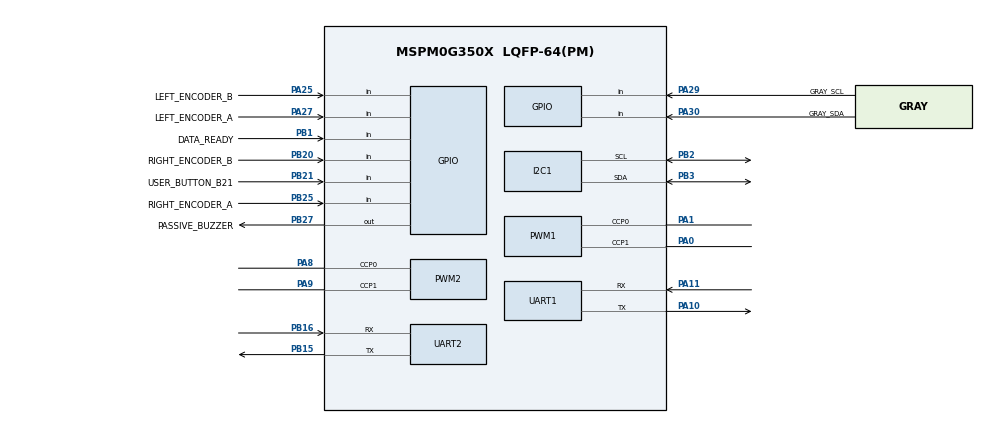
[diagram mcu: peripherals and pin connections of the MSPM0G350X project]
/**
 * @cliArgs --device "MSPM0G350X" --part "Default" --package "LQFP-64(PM)" --product "mspm0_sdk@2.11.00.07"
 * @versions {"tool":"1.26.2+4477"}
 */

/**
 * Import the modules used in this configuration.
 */
const GPIO   = scripting.addModule("/ti/driverlib/GPIO", {}, false);
const GPIO1  = GPIO.addInstance();
const GPIO2  = GPIO.addInstance();
const GPIO3  = GPIO.addInstance();
const GPIO4  = GPIO.addInstance();
const GPIO5  = GPIO.addInstance();
const I2C    = scripting.addModule("/ti/driverlib/I2C", {}, false);
const I2C1   = I2C.addInstance();
const PWM    = scripting.addModule("/ti/driverlib/PWM", {}, false);
const PWM1   = PWM.addInstance();
const PWM2   = PWM.addInstance();
const SYSCTL = scripting.addModule("/ti/driverlib/SYSCTL");
const TIMER  = scripting.addModule("/ti/driverlib/TIMER", {}, false);
const TIMER1 = TIMER.addInstance();
const UART   = scripting.addModule("/ti/driverlib/UART", {}, false);
const UART1  = UART.addInstance();
const UART2  = UART.addInstance();

/**
 * Write custom configuration values to the imported modules.
 */
GPIO1.$name                         = "ENCODERS";
GPIO1.associatedPins.create(4);
GPIO1.associatedPins[0].$name       = "LEFT_ENCODER_A";
GPIO1.associatedPins[0].direction   = "INPUT";
GPIO1.associatedPins[0].interruptEn = true;
GPIO1.associatedPins[0].polarity    = "RISE";
GPIO1.associatedPins[0].pin.$assign = "PA27";
GPIO1.associatedPins[1].$name       = "LEFT_ENCODER_B";
GPIO1.associatedPins[1].direction   = "INPUT";
GPIO1.associatedPins[1].pin.$assign = "PA25";
GPIO1.associatedPins[2].$name       = "RIGHT_ENCODER_A";
GPIO1.associatedPins[2].direction   = "INPUT";
GPIO1.associatedPins[2].interruptEn = true;
GPIO1.associatedPins[2].polarity    = "RISE";
GPIO1.associatedPins[2].pin.$assign = "PB25";
GPIO1.associatedPins[3].$name       = "RIGHT_ENCODER_B";
GPIO1.associatedPins[3].direction   = "INPUT";
GPIO1.associatedPins[3].pin.$assign = "PB20";

const Board = scripting.addModule("/ti/driverlib/Board", {}, false);

GPIO2.$name                              = "START_BUTTON";
GPIO2.associatedPins[0].$name            = "USER_BUTTON_B21";
GPIO2.associatedPins[0].direction        = "INPUT";
GPIO2.associatedPins[0].internalResistor = "PULL_UP";
GPIO2.associatedPins[0].pin.$assign      = "PB21";

GPIO3.$name                         = "MPU6050_INT";
GPIO3.associatedPins[0].$name       = "DATA_READY";
GPIO3.associatedPins[0].direction   = "INPUT";
GPIO3.associatedPins[0].interruptEn = true;
GPIO3.associatedPins[0].polarity    = "RISE";
GPIO3.associatedPins[0].pin.$assign = "PB1";

GPIO4.$name                         = "BEEPER";
GPIO4.associatedPins[0].$name       = "PASSIVE_BUZZER";
GPIO4.associatedPins[0].pin.$assign = "PB27";

/* PA29/PA30 are reserved for the NCHD1/NCHD12 software-I2C gray sensor.
 * The driver changes these two pins between released-input and driven-low
 * states to emulate an open-drain bus.  They start released with pull-ups. */
GPIO5.$name                              = "GRAY_SENSOR_BUS";
GPIO5.associatedPins.create(2);
GPIO5.associatedPins[0].$name            = "GRAY_SCL";
GPIO5.associatedPins[0].direction        = "INPUT";
GPIO5.associatedPins[0].internalResistor = "PULL_UP";
GPIO5.associatedPins[0].pin.$assign      = "PA29";
GPIO5.associatedPins[1].$name            = "GRAY_SDA";
GPIO5.associatedPins[1].direction        = "INPUT";
GPIO5.associatedPins[1].internalResistor = "PULL_UP";
GPIO5.associatedPins[1].pin.$assign      = "PA30";

I2C1.$name                             = "MPU6050_I2C";
I2C1.basicEnableController             = true;
I2C1.basicControllerStandardBusSpeed   = "Fast";
I2C1.peripheral.$assign                = "I2C1";
I2C1.peripheral.sdaPin.$assign         = "PB3";
I2C1.peripheral.sclPin.$assign         = "PB2";
I2C1.sdaPinConfig.$name                = "ti_driverlib_gpio_GPIOPinGeneric8";
I2C1.sdaPinConfig.hideOutputInversion  = scripting.forceWrite(false);
I2C1.sdaPinConfig.onlyInternalResistor = scripting.forceWrite(false);
I2C1.sdaPinConfig.passedPeripheralType = scripting.forceWrite("Digital");
I2C1.sdaPinConfig.enableConfig         = true;
I2C1.sdaPinConfig.internalResistor     = "PULL_UP";
I2C1.sclPinConfig.$name                = "ti_driverlib_gpio_GPIOPinGeneric9";
I2C1.sclPinConfig.hideOutputInversion  = scripting.forceWrite(false);
I2C1.sclPinConfig.onlyInternalResistor = scripting.forceWrite(false);
I2C1.sclPinConfig.passedPeripheralType = scripting.forceWrite("Digital");
I2C1.sclPinConfig.enableConfig         = true;
I2C1.sclPinConfig.internalResistor     = "PULL_UP";

PWM1.$name                              = "MOTOR_A_PWM";
PWM1.timerCount                         = 3200;
PWM1.timerStartTimer                    = true;
PWM1.pwmMode                            = "EDGE_ALIGN_UP";
PWM1.peripheral.$assign                 = "TIMG8";
PWM1.peripheral.ccp0Pin.$assign         = "PA1";
PWM1.peripheral.ccp1Pin.$assign         = "PA0";
PWM1.PWM_CHANNEL_0.$name                = "AIN2_PWM";
PWM1.PWM_CHANNEL_1.$name                = "AIN1_PWM";
PWM1.ccp0PinConfig.$name                = "ti_driverlib_gpio_GPIOPinGeneric0";
PWM1.ccp0PinConfig.direction            = scripting.forceWrite("OUTPUT");
PWM1.ccp0PinConfig.hideOutputInversion  = scripting.forceWrite(false);
PWM1.ccp0PinConfig.onlyInternalResistor = scripting.forceWrite(false);
PWM1.ccp0PinConfig.passedPeripheralType = scripting.forceWrite("Digital");
PWM1.ccp1PinConfig.$name                = "ti_driverlib_gpio_GPIOPinGeneric1";
PWM1.ccp1PinConfig.direction            = scripting.forceWrite("OUTPUT");
PWM1.ccp1PinConfig.hideOutputInversion  = scripting.forceWrite(false);
PWM1.ccp1PinConfig.onlyInternalResistor = scripting.forceWrite(false);
PWM1.ccp1PinConfig.passedPeripheralType = scripting.forceWrite("Digital");

PWM2.$name                              = "MOTOR_B_PWM";
PWM2.timerCount                         = 3200;
PWM2.timerStartTimer                    = true;
PWM2.pwmMode                            = "EDGE_ALIGN_UP";
PWM2.peripheral.$assign                 = "TIMA0";
PWM2.peripheral.ccp0Pin.$assign         = "PA8";
PWM2.peripheral.ccp1Pin.$assign         = "PA9";
PWM2.PWM_CHANNEL_0.$name                = "BIN1_PWM";
PWM2.PWM_CHANNEL_1.$name                = "BIN2_PWM";
PWM2.ccp0PinConfig.$name                = "ti_driverlib_gpio_GPIOPinGeneric2";
PWM2.ccp0PinConfig.direction            = scripting.forceWrite("OUTPUT");
PWM2.ccp0PinConfig.hideOutputInversion  = scripting.forceWrite(false);
PWM2.ccp0PinConfig.onlyInternalResistor = scripting.forceWrite(false);
PWM2.ccp0PinConfig.passedPeripheralType = scripting.forceWrite("Digital");
PWM2.ccp1PinConfig.$name                = "ti_driverlib_gpio_GPIOPinGeneric3";
PWM2.ccp1PinConfig.direction            = scripting.forceWrite("OUTPUT");
PWM2.ccp1PinConfig.hideOutputInversion  = scripting.forceWrite(false);
PWM2.ccp1PinConfig.onlyInternalResistor = scripting.forceWrite(false);
PWM2.ccp1PinConfig.passedPeripheralType = scripting.forceWrite("Digital");

SYSCTL.forceDefaultClkConfig = true;

TIMER1.$name              = "CONTROL_TICK";
TIMER1.timerMode          = "PERIODIC";
TIMER1.timerPeriod        = "5 ms";
TIMER1.timerStartTimer    = true;
TIMER1.interrupts         = ["ZERO"];
TIMER1.peripheral.$assign = "TIMG12";

/* Tianmengxing onboard CH340E: PA10=UART0_TX, PA11=UART0_RX. */
UART1.$name                            = "DEBUG_UART";
UART1.enableFIFO                       = true;
UART1.rxFifoThreshold                  = "DL_UART_RX_FIFO_LEVEL_ONE_ENTRY";
UART1.txFifoThreshold                  = "DL_UART_TX_FIFO_LEVEL_3_4_EMPTY";
UART1.targetBaudRate                   = 115200;
UART1.enabledInterrupts                = ["RX"];
UART1.peripheral.$assign               = "UART0";
UART1.peripheral.rxPin.$assign         = "PA11";
UART1.peripheral.txPin.$assign         = "PA10";
UART1.txPinConfig.$name                = "ti_driverlib_gpio_GPIOPinGeneric4";
UART1.txPinConfig.direction            = scripting.forceWrite("OUTPUT");
UART1.txPinConfig.hideOutputInversion  = scripting.forceWrite(false);
UART1.txPinConfig.onlyInternalResistor = scripting.forceWrite(false);
UART1.txPinConfig.passedPeripheralType = scripting.forceWrite("Digital");
UART1.rxPinConfig.$name                = "ti_driverlib_gpio_GPIOPinGeneric5";
UART1.rxPinConfig.hideOutputInversion  = scripting.forceWrite(false);
UART1.rxPinConfig.onlyInternalResistor = scripting.forceWrite(false);
UART1.rxPinConfig.passedPeripheralType = scripting.forceWrite("Digital");

UART2.$name                            = "JY61_UART";
UART2.enableFIFO                       = true;
UART2.rxFifoThreshold                  = "DL_UART_RX_FIFO_LEVEL_ONE_ENTRY";
UART2.txFifoThreshold                  = "DL_UART_TX_FIFO_LEVEL_3_4_EMPTY";
UART2.targetBaudRate                   = 115200;
UART2.enabledInterrupts                = ["RX"];
UART2.peripheral.$assign               = "UART2";
UART2.peripheral.rxPin.$assign         = "PB16";
UART2.peripheral.txPin.$assign         = "PB15";
UART2.txPinConfig.$name                = "ti_driverlib_gpio_GPIOPinGeneric6";
UART2.txPinConfig.direction            = scripting.forceWrite("OUTPUT");
UART2.txPinConfig.hideOutputInversion  = scripting.forceWrite(false);
UART2.txPinConfig.onlyInternalResistor = scripting.forceWrite(false);
UART2.txPinConfig.passedPeripheralType = scripting.forceWrite("Digital");
UART2.rxPinConfig.$name                = "ti_driverlib_gpio_GPIOPinGeneric7";
UART2.rxPinConfig.hideOutputInversion  = scripting.forceWrite(false);
UART2.rxPinConfig.onlyInternalResistor = scripting.forceWrite(false);
UART2.rxPinConfig.passedPeripheralType = scripting.forceWrite("Digital");

/**
 * Pinmux solution for unlocked pins/peripherals. This ensures that minor changes to the automatic solver in a future
 * version of the tool will not impact the pinmux you originally saw.  These lines can be completely deleted in order to
 * re-solve from scratch.
 */
Board.peripheral.$suggestSolution          = "DEBUGSS";
Board.peripheral.swclkPin.$suggestSolution = "PA20";
Board.peripheral.swdioPin.$suggestSolution = "PA19";
SYSCTL.peripheral.$suggestSolution         = "SYSCTL";
